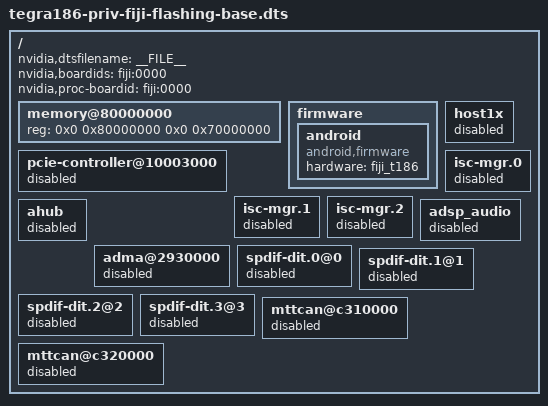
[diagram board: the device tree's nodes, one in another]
/*
 * tegra186-priv-vcm31-p2379-flashing-base.dts: P2379 (Drive-PX2) flashing dts
 * file
 *
 * Copyright (c) 2016, NVIDIA CORPORATION.  All rights reserved.
 *
 * This program is free software; you can redistribute it and/or modify
 * it under the terms of the GNU General Public License as published by
 * the Free Software Foundation; version 2 of the License.
 *
 * This program is distributed in the hope that it will be useful, but WITHOUT
 * ANY WARRANTY; without even the implied warranty of MERCHANTABILITY or
 * FITNESS FOR A PARTICULAR PURPOSE.  See the GNU General Public License for
 * more details.
 */

#include "tegra186-platforms/tegra186-vcm31-p2379-common.dtsi"

/ {
	nvidia,dtsfilename = __FILE__;
	nvidia,boardids = "fiji:0000";
	nvidia,proc-boardid = "fiji:0000";

	memory@80000000 {
		device_type = "memory";
		reg = <0x0 0x80000000 0x0 0x70000000>;
	};

	firmware {
		android {
			compatible = "android,firmware";
			hardware = "fiji_t186";
		};
	};

	/* Disable display */
	host1x {
		status = "disabled";
	};

	/* Disable pci */
	pcie-controller@10003000 {
		status = "disabled";
	};

	/* Disable camera */
	isc-mgr.0 {
		status = "disabled";
	};

	isc-mgr.1 {
		status = "disabled";
	};

	isc-mgr.2 {
		status = "disabled";
	};

	/* Disable audio */
	ahub {
		status = "disabled";
	};

	adma@2930000{
		status = "disabled";
	};

	adsp_audio {
		status = "disabled";
	};

	spdif-dit.0@0 {
		status = "disabled";
	};

	spdif-dit.1@1 {
		status = "disabled";
	};

	spdif-dit.2@2 {
		status = "disabled";
	};

	spdif-dit.3@3 {
		status = "disabled";
	};

	/* Disable can */
	mttcan@c310000 {
		status = "disabled";
	};

	mttcan@c320000 {
		status = "disabled";
	};

};
